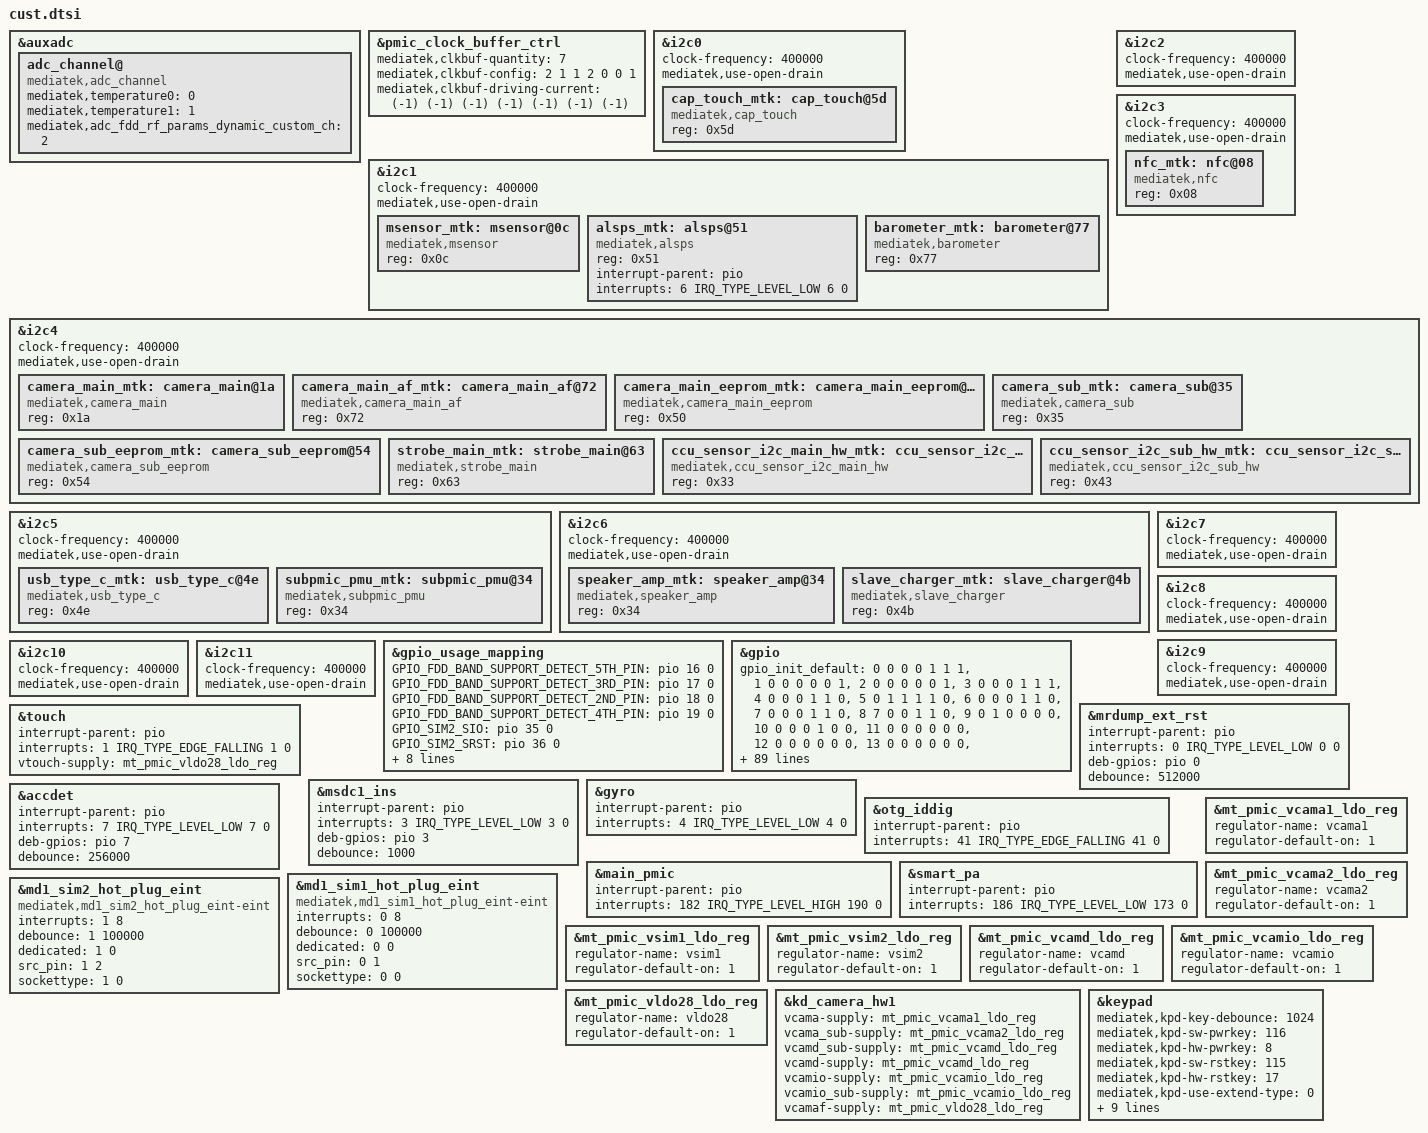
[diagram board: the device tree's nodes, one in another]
/*
 * Generated by MTK SP DrvGen Version: 3.5.160809 for MT6771.
 * 2020-07-30 19:19:25
 * Do Not Modify The File.
 * Copyright Mediatek Inc. (c) 2016.
*/

/*************************
 * ADC DTSI File
*************************/

&auxadc {
	adc_channel@ {
		compatible = "mediatek,adc_channel";
		mediatek,temperature0 = <0>;
		mediatek,temperature1 = <1>;
		mediatek,adc_fdd_rf_params_dynamic_custom_ch = <2>;
		status = "okay";
	};
};


/*************************
 * CLK_BUF DTSI File
*************************/

&pmic_clock_buffer_ctrl {
	mediatek,clkbuf-quantity = <7>;
	mediatek,clkbuf-config = <2 1 1 2 0 0 1>;
	mediatek,clkbuf-driving-current = <(-1) (-1) (-1) (-1) (-1) (-1) (-1)>;
	status = "okay";
};


/*************************
 * I2C DTSI File
*************************/

&i2c0 {
	#address-cells = <1>;
	#size-cells = <0>;
	clock-frequency = <400000>;
	mediatek,use-open-drain;
	cap_touch_mtk:cap_touch@5d {
		compatible = "mediatek,cap_touch";
		reg = <0x5d>;
		status = "okay";
	};

};

&i2c1 {
	#address-cells = <1>;
	#size-cells = <0>;
	clock-frequency = <400000>;
	mediatek,use-open-drain;
	msensor_mtk:msensor@0c {
		compatible = "mediatek,msensor";
		reg = <0x0c>;
		status = "okay";
	};

	alsps_mtk:alsps@51 {
		compatible = "mediatek,alsps";
		reg = <0x51>;
		status = "okay";
	};

	barometer_mtk:barometer@77 {
		compatible = "mediatek,barometer";
		reg = <0x77>;
		status = "okay";
	};

};

&i2c2 {
	#address-cells = <1>;
	#size-cells = <0>;
	clock-frequency = <400000>;
	mediatek,use-open-drain;
};

&i2c3 {
	#address-cells = <1>;
	#size-cells = <0>;
	clock-frequency = <400000>;
	mediatek,use-open-drain;
	nfc_mtk:nfc@08 {
		compatible = "mediatek,nfc";
		reg = <0x08>;
		status = "okay";
	};

};

&i2c4 {
	#address-cells = <1>;
	#size-cells = <0>;
	clock-frequency = <400000>;
	mediatek,use-open-drain;
	camera_main_mtk:camera_main@1a {
		compatible = "mediatek,camera_main";
		reg = <0x1a>;
		status = "okay";
	};

	camera_main_af_mtk:camera_main_af@72 {
		compatible = "mediatek,camera_main_af";
		reg = <0x72>;
		status = "okay";
	};

	camera_main_eeprom_mtk:camera_main_eeprom@50 {
		compatible = "mediatek,camera_main_eeprom";
		reg = <0x50>;
		status = "okay";
	};

	camera_sub_mtk:camera_sub@35 {
		compatible = "mediatek,camera_sub";
		reg = <0x35>;
		status = "okay";
	};

	camera_sub_eeprom_mtk:camera_sub_eeprom@54 {
		compatible = "mediatek,camera_sub_eeprom";
		reg = <0x54>;
		status = "okay";
	};

	strobe_main_mtk:strobe_main@63 {
		compatible = "mediatek,strobe_main";
		reg = <0x63>;
		status = "okay";
	};

	ccu_sensor_i2c_main_hw_mtk:ccu_sensor_i2c_main_hw@33 {
		compatible = "mediatek,ccu_sensor_i2c_main_hw";
		reg = <0x33>;
		status = "okay";
	};

	ccu_sensor_i2c_sub_hw_mtk:ccu_sensor_i2c_sub_hw@43 {
		compatible = "mediatek,ccu_sensor_i2c_sub_hw";
		reg = <0x43>;
		status = "okay";
	};

};

&i2c5 {
	#address-cells = <1>;
	#size-cells = <0>;
	clock-frequency = <400000>;
	mediatek,use-open-drain;
	usb_type_c_mtk:usb_type_c@4e {
		compatible = "mediatek,usb_type_c";
		reg = <0x4e>;
		status = "okay";
	};

	subpmic_pmu_mtk:subpmic_pmu@34 {
		compatible = "mediatek,subpmic_pmu";
		reg = <0x34>;
		status = "okay";
	};

};

&i2c6 {
	#address-cells = <1>;
	#size-cells = <0>;
	clock-frequency = <400000>;
	mediatek,use-open-drain;
	speaker_amp_mtk:speaker_amp@34 {
		compatible = "mediatek,speaker_amp";
		reg = <0x34>;
		status = "okay";
	};

	slave_charger_mtk:slave_charger@4b {
		compatible = "mediatek,slave_charger";
		reg = <0x4b>;
		status = "okay";
	};

};

&i2c7 {
	#address-cells = <1>;
	#size-cells = <0>;
	clock-frequency = <400000>;
	mediatek,use-open-drain;
};

&i2c8 {
	#address-cells = <1>;
	#size-cells = <0>;
	clock-frequency = <400000>;
	mediatek,use-open-drain;
};

&i2c9 {
	#address-cells = <1>;
	#size-cells = <0>;
	clock-frequency = <400000>;
	mediatek,use-open-drain;
};

&i2c10 {
	#address-cells = <1>;
	#size-cells = <0>;
	clock-frequency = <400000>;
	mediatek,use-open-drain;
};

&i2c11 {
	#address-cells = <1>;
	#size-cells = <0>;
	clock-frequency = <400000>;
	mediatek,use-open-drain;
};



/*************************
 * GPIO DTSI File
*************************/

&gpio_usage_mapping {
	GPIO_FDD_BAND_SUPPORT_DETECT_5TH_PIN = <&pio 16 0>;
	GPIO_FDD_BAND_SUPPORT_DETECT_3RD_PIN = <&pio 17 0>;
	GPIO_FDD_BAND_SUPPORT_DETECT_2ND_PIN = <&pio 18 0>;
	GPIO_FDD_BAND_SUPPORT_DETECT_4TH_PIN = <&pio 19 0>;
	GPIO_SIM2_SIO = <&pio 35 0>;
	GPIO_SIM2_SRST = <&pio 36 0>;
	GPIO_SIM2_SCLK = <&pio 37 0>;
	GPIO_SIM1_SCLK = <&pio 38 0>;
	GPIO_SIM1_SRST = <&pio 39 0>;
	GPIO_SIM1_SIO = <&pio 40 0>;
	GPIO_SIM2_HOT_PLUG = <&pio 46 0>;
	GPIO_SIM1_HOT_PLUG = <&pio 47 0>;
	GPIO_FDD_BAND_SUPPORT_DETECT_1ST_PIN = <&pio 165 0>;
};

&gpio{
	gpio_init_default = <0 0 0 0 1 1 1>,
		<1 0 0 0 0 0 1>,
		<2 0 0 0 0 0 1>,
		<3 0 0 0 1 1 1>,
		<4 0 0 0 1 1 0>,
		<5 0 1 1 1 1 0>,
		<6 0 0 0 1 1 0>,
		<7 0 0 0 1 1 0>,
		<8 7 0 0 1 1 0>,
		<9 0 1 0 0 0 0>,
		<10 0 0 0 1 0 0>,
		<11 0 0 0 0 0 0>,
		<12 0 0 0 0 0 0>,
		<13 0 0 0 0 0 0>,
		<14 0 0 0 0 0 0>,
		<15 0 0 0 0 0 0>,
		<16 0 0 0 1 0 0>,
		<17 0 0 0 1 0 0>,
		<18 0 0 0 1 0 0>,
		<19 0 0 0 1 0 0>,
		<20 0 0 0 0 0 0>,
		<21 0 0 0 1 0 0>,
		<22 4 0 0 1 0 0>,
		<23 0 1 0 0 0 0>,
		<24 0 1 0 0 0 0>,
		<25 0 0 0 0 0 0>,
		<26 0 0 0 0 0 0>,
		<27 0 0 0 0 0 0>,
		<28 0 0 0 0 0 0>,
		<29 1 1 0 0 0 0>,
		<30 1 0 0 1 1 0>,
		<31 1 0 0 1 1 0>,
		<32 1 0 0 1 1 0>,
		<33 1 0 0 1 1 0>,
		<34 1 0 0 1 1 0>,
		<35 1 0 0 1 1 0>,
		<36 1 1 0 0 0 0>,
		<37 1 1 0 0 0 0>,
		<38 1 1 0 0 0 0>,
		<39 1 1 0 0 0 0>,
		<40 1 0 0 1 1 0>,
		<41 0 0 0 1 1 0>,
		<42 0 0 0 1 0 0>,
		<43 0 0 0 1 0 0>,
		<44 1 0 0 1 0 0>,
		<45 0 1 0 0 0 0>,
		<46 1 0 0 1 1 0>,
		<47 1 0 0 1 1 0>,
		<48 1 0 0 0 0 0>,
		<49 1 0 0 0 0 0>,
		<50 1 0 0 0 0 0>,
		<51 1 0 0 0 0 0>,
		<52 1 1 0 1 0 0>,
		<53 1 1 0 1 0 0>,
		<54 1 1 0 1 0 0>,
		<55 1 1 0 1 0 0>,
		<56 1 1 0 1 0 0>,
		<57 1 1 0 1 0 0>,
		<58 0 0 0 1 1 0>,
		<59 1 0 0 1 0 0>,
		<60 1 0 0 1 0 0>,
		<61 1 0 0 1 0 0>,
		<62 1 0 0 1 0 0>,
		<63 1 0 0 1 0 0>,
		<64 1 0 0 1 0 0>,
		<65 0 1 0 0 0 0>,
		<66 2 0 0 1 0 0>,
		<67 1 0 0 1 0 0>,
		<68 1 0 0 1 0 0>,
		<69 1 1 0 1 0 0>,
		<70 1 1 0 1 0 0>,
		<71 1 1 0 1 0 0>,
		<72 1 1 0 1 0 0>,
		<73 1 1 0 1 0 0>,
		<74 1 1 0 1 0 0>,
		<75 0 0 0 1 0 0>,
		<76 0 0 0 1 0 0>,
		<77 1 1 0 1 0 0>,
		<78 1 1 0 1 0 0>,
		<79 0 0 0 1 0 0>,
		<80 0 0 0 1 0 0>,
		<81 1 0 0 1 1 0>,
		<82 1 0 0 0 0 0>,
		<83 1 0 0 0 0 0>,
		<84 1 0 0 1 1 0>,
		<85 0 0 0 1 0 0>,
		<86 0 0 0 1 0 0>,
		<87 0 0 0 1 0 0>,
		<88 0 0 0 1 0 0>,
		<89 0 0 0 1 0 0>,
		<90 0 1 0 1 1 0>,
		<91 0 1 0 0 0 0>,
		<92 0 0 0 0 0 0>,
		<93 1 0 0 1 1 0>,
		<94 0 0 0 0 0 0>,
		<95 1 0 0 1 1 0>,
		<96 1 1 0 0 0 0>,
		<97 0 0 0 1 0 0>,
		<98 0 1 0 0 0 0>,
		<99 0 0 0 1 0 0>,
		<100 0 1 0 0 0 0>,
		<101 0 0 0 1 0 0>,
		<102 0 1 0 0 0 0>,
		<103 0 0 0 0 0 0>,
		<104 0 0 0 0 0 0>,
		<105 1 0 0 0 0 0>,
		<106 1 0 0 0 0 0>,
		<107 0 1 0 0 0 0>,
		<108 0 1 0 0 0 0>,
		<109 0 1 0 0 0 0>,
		<110 0 0 0 0 0 0>,
		<111 0 0 0 0 0 0>,
		<112 0 0 0 0 0 0>,
		<113 0 0 0 1 0 0>,
		<114 0 0 0 1 0 0>,
		<115 0 0 0 1 0 0>,
		<116 0 0 0 1 0 0>,
		<117 0 0 0 1 0 0>,
		<118 0 0 0 1 0 0>,
		<119 0 0 0 1 0 0>,
		<120 0 0 0 1 0 0>,
		<121 0 0 0 1 0 0>,
		<122 1 0 0 1 1 0>,
		<123 1 0 0 1 1 0>,
		<124 1 1 0 0 0 0>,
		<125 1 0 0 1 1 0>,
		<126 1 0 0 1 1 0>,
		<127 1 0 0 1 1 0>,
		<128 1 0 0 1 1 0>,
		<129 1 0 0 1 1 0>,
		<130 1 0 0 1 1 0>,
		<131 1 0 0 1 0 0>,
		<132 1 0 0 1 1 0>,
		<133 1 1 1 0 0 0>,
		<134 1 0 0 1 0 1>,
		<135 1 1 0 0 0 0>,
		<136 1 1 0 0 0 0>,
		<137 1 1 0 0 0 0>,
		<138 1 1 0 0 0 0>,
		<139 1 1 0 0 0 0>,
		<140 1 0 0 1 0 0>,
		<141 1 0 0 1 0 0>,
		<142 1 0 0 1 0 0>,
		<143 1 0 0 1 0 0>,
		<144 1 0 0 1 0 0>,
		<145 1 1 1 0 0 0>,
		<146 1 0 0 1 0 0>,
		<147 1 1 0 0 0 0>,
		<148 1 1 0 0 0 0>,
		<149 1 1 0 0 0 0>,
		<150 0 1 0 0 0 0>,
		<151 0 1 0 0 0 0>,
		<152 0 1 0 0 0 0>,
		<153 0 1 0 0 0 0>,
		<154 1 1 0 0 0 0>,
		<155 1 0 0 1 0 0>,
		<156 1 0 0 1 0 0>,
		<157 1 0 0 1 0 0>,
		<158 0 0 0 1 0 0>,
		<159 0 0 0 1 1 0>,
		<160 0 0 0 0 0 0>,
		<161 2 0 0 1 0 0>,
		<162 2 1 1 0 0 0>,
		<163 2 1 0 0 0 0>,
		<164 2 1 0 0 0 0>,
		<165 0 0 0 1 0 0>,
		<166 0 0 0 1 0 0>,
		<167 1 1 0 1 0 0>,
		<168 1 1 0 1 0 0>,
		<169 0 1 0 0 0 0>,
		<170 0 0 0 1 0 0>,
		<171 0 0 0 1 0 0>,
		<172 0 0 0 1 0 0>,
		<173 0 0 0 0 0 0>,
		<174 2 0 0 1 0 0>,
		<175 0 0 0 1 1 0>,
		<176 0 0 0 1 1 0>,
		<177 0 0 0 1 1 0>,
		<178 0 0 0 1 1 0>,
		<179 0 0 0 1 1 0>,
		<180 0 0 0 1 0 0>,
		<181 0 0 0 1 0 0>,
		<182 0 0 0 1 0 0>,
		<183 0 0 0 1 0 0>,
		<184 0 0 0 1 0 0>,
		<185 0 0 0 1 0 0>,
		<186 0 0 0 1 0 0>,
		<187 0 0 0 1 0 0>,
		<188 0 0 0 1 0 0>,
		<189 0 0 0 1 0 0>,
		<190 0 0 0 1 0 0>,
		<191 0 0 0 1 0 0>;
};


/*************************
 * EINT DTSI File
*************************/

#include <dt-bindings/interrupt-controller/irq.h>
#include <dt-bindings/interrupt-controller/arm-gic.h>

&mrdump_ext_rst {
	interrupt-parent = <&pio>;
	interrupts = <0 IRQ_TYPE_LEVEL_LOW 0 0>;
	deb-gpios = <&pio 0 0>;
	debounce = <512000>;
	status = "okay";
};

&touch {
	interrupt-parent = <&pio>;
	interrupts = <1 IRQ_TYPE_EDGE_FALLING 1 0>;
	status = "okay";
};

&msdc1_ins {
	interrupt-parent = <&pio>;
	interrupts = <3 IRQ_TYPE_LEVEL_LOW 3 0>;
	deb-gpios = <&pio 3 0>;
	debounce = <1000>;
	status = "okay";
};

&gyro {
	interrupt-parent = <&pio>;
	interrupts = <4 IRQ_TYPE_LEVEL_LOW 4 0>;
	status = "okay";
};

&alsps_mtk {
	interrupt-parent = <&pio>;
	interrupts = <6 IRQ_TYPE_LEVEL_LOW 6 0>;
	status = "okay";
};

&accdet {
	interrupt-parent = <&pio>;
	interrupts = <7 IRQ_TYPE_LEVEL_LOW 7 0>;
	deb-gpios = <&pio 7 0>;
	debounce = <256000>;
	status = "okay";
};

&otg_iddig {
	interrupt-parent = <&pio>;
	interrupts = <41 IRQ_TYPE_EDGE_FALLING 41 0>;
	status = "okay";
};

&main_pmic {
	interrupt-parent = <&pio>;
	interrupts = <182 IRQ_TYPE_LEVEL_HIGH 190 0>;
	status = "okay";
};

&smart_pa {
	interrupt-parent = <&pio>;
	interrupts = <186 IRQ_TYPE_LEVEL_LOW 173 0>;
	status = "okay";
};



/*************************
 * MD1_EINT DTSI File
*************************/

&md1_sim1_hot_plug_eint {
	compatible = "mediatek,md1_sim1_hot_plug_eint-eint";
	interrupts = <0 8>;
	debounce = <0 100000>;
	dedicated = <0 0>;
	src_pin = <0 1>;
	sockettype = <0 0>;
	status = "okay";
};

&md1_sim2_hot_plug_eint {
	compatible = "mediatek,md1_sim2_hot_plug_eint-eint";
	interrupts = <1 8>;
	debounce = <1 100000>;
	dedicated = <1 0>;
	src_pin = <1 2>;
	sockettype = <1 0>;
	status = "okay";
};



/*************************
 * PMIC DTSI File
*************************/

&mt_pmic_vcama1_ldo_reg {
	regulator-name = "vcama1";
	regulator-default-on = <1>; /* 0:skip, 1: off, 2:on */
	status = "okay";
};
&mt_pmic_vcama2_ldo_reg {
	regulator-name = "vcama2";
	regulator-default-on = <1>; /* 0:skip, 1: off, 2:on */
	status = "okay";
};
&mt_pmic_vsim1_ldo_reg {
	regulator-name = "vsim1";
	regulator-default-on = <1>; /* 0:skip, 1: off, 2:on */
	status = "okay";
};
&mt_pmic_vsim2_ldo_reg {
	regulator-name = "vsim2";
	regulator-default-on = <1>; /* 0:skip, 1: off, 2:on */
	status = "okay";
};
&mt_pmic_vcamd_ldo_reg {
	regulator-name = "vcamd";
	regulator-default-on = <1>; /* 0:skip, 1: off, 2:on */
	status = "okay";
};
&mt_pmic_vcamio_ldo_reg {
	regulator-name = "vcamio";
	regulator-default-on = <1>; /* 0:skip, 1: off, 2:on */
	status = "okay";
};
&mt_pmic_vldo28_ldo_reg {
	regulator-name = "vldo28";
	regulator-default-on = <1>; /* 0:skip, 1: off, 2:on */
	status = "okay";
};

&kd_camera_hw1 {
	vcama-supply = <&mt_pmic_vcama1_ldo_reg>;
	vcama_sub-supply = <&mt_pmic_vcama2_ldo_reg>;
	vcamd_sub-supply = <&mt_pmic_vcamd_ldo_reg>;
	vcamd-supply = <&mt_pmic_vcamd_ldo_reg>;
	vcamio-supply = <&mt_pmic_vcamio_ldo_reg>;
	vcamio_sub-supply = <&mt_pmic_vcamio_ldo_reg>;
	vcamaf-supply = <&mt_pmic_vldo28_ldo_reg>;
	status = "okay";
};

&touch {
	vtouch-supply = <&mt_pmic_vldo28_ldo_reg>;
	status = "okay";
};


/*************************
 * POWER DTSI File
*************************/



/*************************
 * KPD DTSI File
*************************/

&keypad {
	mediatek,kpd-key-debounce = <1024>;
	mediatek,kpd-sw-pwrkey = <116>;
	mediatek,kpd-hw-pwrkey = <8>;
	mediatek,kpd-sw-rstkey  = <115>;
	mediatek,kpd-hw-rstkey = <17>;
	mediatek,kpd-use-extend-type = <0>;
	/*HW Keycode [0~71] -> Linux Keycode*/
	mediatek,kpd-hw-map-num = <72>;
	mediatek,kpd-hw-init-map = <114 0 0 0 0 0 0 0 0 0 0 0 0 0 0 0 0 0 0 0 0 0 0 0 0 0 0 0 0 0 0 0 0 0 0 0 0 0 0 0 0 0 0 0 0 0 0 0 0 0 0 0 0 0 0 0 0 0 0 0 0 0 0 0 0 0 0 0 0 0 0 0 >;
	mediatek,kpd-pwrkey-eint-gpio = <0>;
	mediatek,kpd-pwkey-gpio-din  = <0>;
	mediatek,kpd-hw-dl-key0 = <17>;
	mediatek,kpd-hw-dl-key1 = <0>;
	mediatek,kpd-hw-dl-key2 = <8>;
	mediatek,kpd-hw-recovery-key = <0>;
	status = "okay";
};


